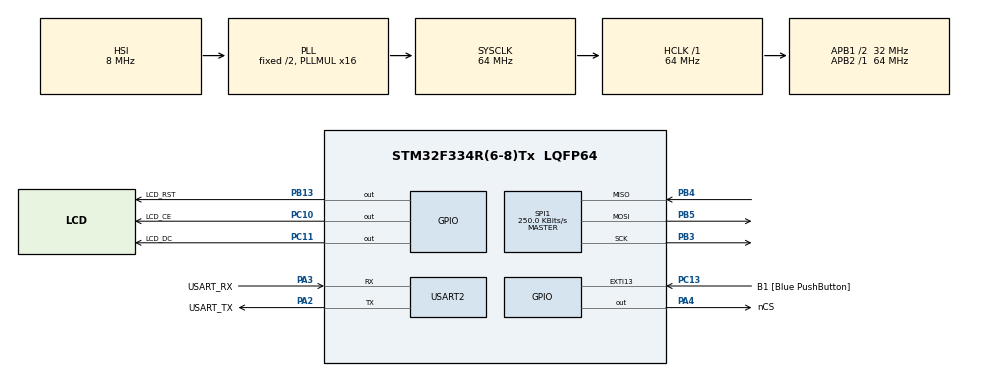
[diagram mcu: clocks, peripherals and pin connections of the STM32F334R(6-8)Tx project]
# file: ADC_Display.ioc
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Mcu.Family=STM32F3
Mcu.Name=STM32F334R(6-8)Tx
Mcu.Package=LQFP64
NVIC.PriorityGroup=NVIC_PRIORITYGROUP_0
PA13.GPIO_Label=TMS
PA13.Mode=Serial_Wire
PA13.Signal=SYS_JTMS-SWDIO
PA14.GPIO_Label=TCK
PA14.Mode=Serial_Wire
PA14.Signal=SYS_JTCK-SWCLK
PA2.GPIO_Label=USART_TX
PA2.Mode=Asynchronous
PA2.Signal=USART2_TX
PA3.GPIO_Label=USART_RX
PA3.Mode=Asynchronous
PA3.Signal=USART2_RX
PA4.GPIO_Label=nCS
PA4.Signal=GPIO_Output
PB13.GPIO_Label=LCD_RST
PB13.Signal=GPIO_Output
PB3.Mode=Full_Duplex_Master
PB3.Signal=SPI1_SCK
PB4.Mode=Full_Duplex_Master
PB4.Signal=SPI1_MISO
PB5.Mode=Full_Duplex_Master
PB5.Signal=SPI1_MOSI
PC10.GPIO_Label=LCD_CE
PC10.Signal=GPIO_Output
PC11.GPIO_Label=LCD_DC
PC11.Signal=GPIO_Output
PC13.GPIO_Label=B1 [Blue PushButton]
PC13.GPIO_ModeDefaultEXTI=GPIO_MODE_IT_FALLING
PC13.Signal=GPXTI13
PC14\ /\ OSC32_IN.Mode=LSE-External-Oscillator
PC14\ /\ OSC32_IN.Signal=RCC_OSC32_IN
PC15\ /\ OSC32_OUT.GPIO_Label=RCC_OSC32_OUT
PC15\ /\ OSC32_OUT.Mode=LSE-External-Oscillator
PC15\ /\ OSC32_OUT.Signal=RCC_OSC32_OUT
PF0\ /\ OSC_IN.Mode=HSE-External-Clock-Source
PF0\ /\ OSC_IN.Signal=RCC_OSC_IN
PF1\ /\ OSC_OUT.Signal=RCC_OSC_OUT
ProjectManager.HeapSize=0x200
ProjectManager.StackSize=0x400
ProjectManager.TargetToolchain=STM32CubeIDE
RCC.AHBFreq_Value=64000000
RCC.APB1CLKDivider=RCC_HCLK_DIV2
RCC.APB1Freq_Value=32000000
RCC.APB1TimFreq_Value=64000000
RCC.APB2Freq_Value=64000000
RCC.APB2TimFreq_Value=64000000
RCC.CortexFreq_Value=64000000
RCC.FLatency-AdvancedSettings=FLASH_LATENCY_2
RCC.HCLKFreq_Value=64000000
RCC.HSE_VALUE=8000000
RCC.HSI_VALUE=8000000
RCC.PLLMUL=RCC_PLL_MUL16
RCC.SYSCLKFreq_VALUE=64000000
RCC.SYSCLKSourceVirtual=RCC_SYSCLKSOURCE_PLLCLK
SPI1.BaudRatePrescaler=SPI_BAUDRATEPRESCALER_256
SPI1.CalculateBaudRate=250.0 KBits/s
SPI1.DataSize=SPI_DATASIZE_8BIT
SPI1.Direction=SPI_DIRECTION_2LINES
SPI1.Mode=SPI_MODE_MASTER
SPI1.VirtualType=VM_MASTER
USART2.VirtualMode-Asynchronous=VM_ASYNC
board=NUCLEO-F334R8

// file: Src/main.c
/* USER CODE BEGIN Header */
/**
  ******************************************************************************
  * @file           : main.c
  * @brief          : Main program body
  ******************************************************************************
  * @attention
  *
  * <h2><center>&copy; Copyright (c) 2019 STMicroelectronics.
  * All rights reserved.</center></h2>
  *
  * This software component is licensed by ST under BSD 3-Clause license,
  * the "License"; You may not use this file except in compliance with the
  * License. You may obtain a copy of the License at:
  *                        opensource.org/licenses/BSD-3-Clause
  *
  ******************************************************************************
  */
/* USER CODE END Header */

#include "main.h"

/* USER CODE BEGIN Includes */
#include "STM32f3xx_HAL.h"
#include "user_5110.h"
/* USER CODE END Includes */

SPI_HandleTypeDef hspi1;

UART_HandleTypeDef huart2;

void SystemClock_Config(void);
static void MX_GPIO_Init(void);
static void MX_USART2_UART_Init(void);
static void MX_SPI1_Init(void);

int main(void)
{

  /* MCU Configuration--------------------------------------------------------*/

  /* Reset of all peripherals, Initializes the Flash interface and the Systick. */
  HAL_Init();

  /* Configure the system clock */
  SystemClock_Config();

  /* Initialize all configured peripherals */
  MX_GPIO_Init();
  MX_USART2_UART_Init();
  MX_SPI1_Init();
  /* USER CODE BEGIN 2 */
  LCD_Init();
  char Buffer[50];
  char init;
  /* USER CODE END 2 */

  /* Infinite loop */
  while (1)
  {
	  HAL_GPIO_WritePin(nCS_GPIO_Port, nCS_Pin, 0);

	  init = "0xC";
	  HAL_SPI_Transmit(&hspi1, &init, nCS_Pin, 1000);

	  HAL_SPI_Receive(&hspi1, &init, nCS_Pin, 1000);

	  HAL_GPIO_WritePin(nCS_GPIO_Port, nCS_Pin, 1);

	  sprintf(Buffer,"%d", init);

	  LCD_Write_String(0,0,Buffer);
	  HAL_Delay(1000);
  }
}

void SystemClock_Config(void)
{
  RCC_OscInitTypeDef RCC_OscInitStruct = {0};
  RCC_ClkInitTypeDef RCC_ClkInitStruct = {0};

  /** Initializes the CPU, AHB and APB busses clocks
  */
  RCC_OscInitStruct.OscillatorType = RCC_OSCILLATORTYPE_HSI;
  RCC_OscInitStruct.HSIState = RCC_HSI_ON;
  RCC_OscInitStruct.HSICalibrationValue = RCC_HSICALIBRATION_DEFAULT;
  RCC_OscInitStruct.PLL.PLLState = RCC_PLL_ON;
  RCC_OscInitStruct.PLL.PLLSource = RCC_PLLSOURCE_HSI;
  RCC_OscInitStruct.PLL.PLLMUL = RCC_PLL_MUL16;
  if (HAL_RCC_OscConfig(&RCC_OscInitStruct) != HAL_OK)
  {
    Error_Handler();
  }
  /** Initializes the CPU, AHB and APB busses clocks
  */
  RCC_ClkInitStruct.ClockType = RCC_CLOCKTYPE_HCLK|RCC_CLOCKTYPE_SYSCLK
                              |RCC_CLOCKTYPE_PCLK1|RCC_CLOCKTYPE_PCLK2;
  RCC_ClkInitStruct.SYSCLKSource = RCC_SYSCLKSOURCE_PLLCLK;
  RCC_ClkInitStruct.AHBCLKDivider = RCC_SYSCLK_DIV1;
  RCC_ClkInitStruct.APB1CLKDivider = RCC_HCLK_DIV2;
  RCC_ClkInitStruct.APB2CLKDivider = RCC_HCLK_DIV1;

  if (HAL_RCC_ClockConfig(&RCC_ClkInitStruct, FLASH_LATENCY_2) != HAL_OK)
  {
    Error_Handler();
  }
}

static void MX_SPI1_Init(void)
{

  /* SPI1 parameter configuration*/
  hspi1.Instance = SPI1;
  hspi1.Init.Mode = SPI_MODE_MASTER;
  hspi1.Init.Direction = SPI_DIRECTION_2LINES;
  hspi1.Init.DataSize = SPI_DATASIZE_8BIT;
  hspi1.Init.CLKPolarity = SPI_POLARITY_LOW;
  hspi1.Init.CLKPhase = SPI_PHASE_1EDGE;
  hspi1.Init.NSS = SPI_NSS_SOFT;
  hspi1.Init.BaudRatePrescaler = SPI_BAUDRATEPRESCALER_256;
  hspi1.Init.FirstBit = SPI_FIRSTBIT_MSB;
  hspi1.Init.TIMode = SPI_TIMODE_DISABLE;
  hspi1.Init.CRCCalculation = SPI_CRCCALCULATION_DISABLE;
  hspi1.Init.CRCPolynomial = 7;
  hspi1.Init.CRCLength = SPI_CRC_LENGTH_DATASIZE;
  hspi1.Init.NSSPMode = SPI_NSS_PULSE_ENABLE;
  if (HAL_SPI_Init(&hspi1) != HAL_OK)
  {
    Error_Handler();
  }

}

static void MX_USART2_UART_Init(void)
{

  huart2.Instance = USART2;
  huart2.Init.BaudRate = 38400;
  huart2.Init.WordLength = UART_WORDLENGTH_8B;
  huart2.Init.StopBits = UART_STOPBITS_1;
  huart2.Init.Parity = UART_PARITY_NONE;
  huart2.Init.Mode = UART_MODE_TX_RX;
  huart2.Init.HwFlowCtl = UART_HWCONTROL_NONE;
  huart2.Init.OverSampling = UART_OVERSAMPLING_16;
  huart2.Init.OneBitSampling = UART_ONE_BIT_SAMPLE_DISABLE;
  huart2.AdvancedInit.AdvFeatureInit = UART_ADVFEATURE_NO_INIT;
  if (HAL_UART_Init(&huart2) != HAL_OK)
  {
    Error_Handler();
  }

}

static void MX_GPIO_Init(void)
{
  GPIO_InitTypeDef GPIO_InitStruct = {0};

  /* GPIO Ports Clock Enable */
  __HAL_RCC_GPIOC_CLK_ENABLE();
  __HAL_RCC_GPIOF_CLK_ENABLE();
  __HAL_RCC_GPIOA_CLK_ENABLE();
  __HAL_RCC_GPIOB_CLK_ENABLE();

  /*Configure GPIO pin Output Level */
  HAL_GPIO_WritePin(nCS_GPIO_Port, nCS_Pin, GPIO_PIN_SET);

  /*Configure GPIO pin Output Level */
  HAL_GPIO_WritePin(LCD_RST_GPIO_Port, LCD_RST_Pin, GPIO_PIN_RESET);

  /*Configure GPIO pin Output Level */
  HAL_GPIO_WritePin(GPIOC, LCD_CE_Pin|LCD_DC_Pin, GPIO_PIN_RESET);

  /*Configure GPIO pin : B1_Pin */
  GPIO_InitStruct.Pin = B1_Pin;
  GPIO_InitStruct.Mode = GPIO_MODE_IT_FALLING;
  GPIO_InitStruct.Pull = GPIO_NOPULL;
  HAL_GPIO_Init(B1_GPIO_Port, &GPIO_InitStruct);

  /*Configure GPIO pin : nCS_Pin */
  GPIO_InitStruct.Pin = nCS_Pin;
  GPIO_InitStruct.Mode = GPIO_MODE_OUTPUT_PP;
  GPIO_InitStruct.Pull = GPIO_NOPULL;
  GPIO_InitStruct.Speed = GPIO_SPEED_FREQ_LOW;
  HAL_GPIO_Init(nCS_GPIO_Port, &GPIO_InitStruct);

  /*Configure GPIO pin : LCD_RST_Pin */
  GPIO_InitStruct.Pin = LCD_RST_Pin;
  GPIO_InitStruct.Mode = GPIO_MODE_OUTPUT_PP;
  GPIO_InitStruct.Pull = GPIO_NOPULL;
  GPIO_InitStruct.Speed = GPIO_SPEED_FREQ_LOW;
  HAL_GPIO_Init(LCD_RST_GPIO_Port, &GPIO_InitStruct);

  /*Configure GPIO pins : LCD_CE_Pin LCD_DC_Pin */
  GPIO_InitStruct.Pin = LCD_CE_Pin|LCD_DC_Pin;
  GPIO_InitStruct.Mode = GPIO_MODE_OUTPUT_PP;
  GPIO_InitStruct.Pull = GPIO_NOPULL;
  GPIO_InitStruct.Speed = GPIO_SPEED_FREQ_LOW;
  HAL_GPIO_Init(GPIOC, &GPIO_InitStruct);

}

void Error_Handler(void)
{
}

/************************ (C) COPYRIGHT STMicroelectronics *****END OF FILE****/
